# BAT32G157 register map
Vendor: Cmsemicon; Series: BAT32G157; File version: 1.0
CPU: CM0+ r0p1, little endian, no MPU, no FPU, VTOR, 2 interrupt priority bits
Registers are 8-bit, read-write, reset 0x0 unless marked. A register's access mark holds for its fields unless they carry their own. Offsets are from the block's base; [hi:lo] are bit positions; {n}, {i} and the like mark numbered series; 'fields as' and 'values as' point back to an identical list.

## USBF — USB Full Speed Module
Base 0x40080000
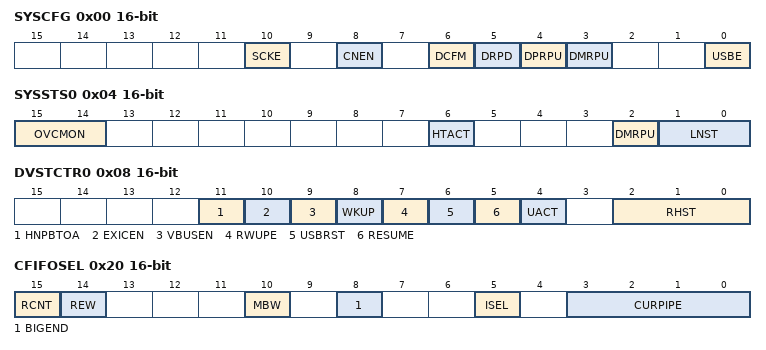
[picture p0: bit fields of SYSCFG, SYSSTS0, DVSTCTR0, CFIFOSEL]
0x00 SYSCFG 16-bit — System Configuration Control Register
  [10] SCKE — USB Clock Enable
  [8] CNEN — CNEN Single-Ended Receiver Enable
  [6] DCFM — Controller Function Select
  [5] DRPD — D+/D- Line Resistor Control
  [4] DPRPU — D+ Line Resistor Control
  [3] DMRPU — D- Line Resistor Control
  [0] USBE — USBFS Operation Enable
0x04 SYSSTS0 16-bit — System Configuration Status Register 0
  [15:14] OVCMON — External USB_OVRCURA/USB_OVRCURB Input Pin Monitor
  [6] HTACT — USB Host Sequencer Status Monitor
  [2] DMRPU — External ID0 Input Pin Monitor
  [1:0] LNST — USB Data Line Status Monitor
0x08 DVSTCTR0 16-bit — Device State Control Register 0
  [11] HNPBTOA — Host Negotiation Protocol (HNP) Control
  [10] EXICEN — USB_EXICEN Output Pin Contro
  [9] VBUSEN — USB_VBUSEN Output Pin Control
  [8] WKUP — Wakeup Output
  [7] RWUPE — Wakeup Detection Enable
  [6] USBRST — USB Bus Reset Output
  [5] RESUME — Resume Output
  [4] UACT — USB Bus Enable
  [2:0] RHST — USB Bus Reset Status
0x14 CFIFO 16-bit — CFIFO Port Register
0x14 CFIFOL (alternate view of CFIFO) — CFIFO Port Register
0x18 D0FIFO 16-bit — D0FIFO Port Register
0x18 D0FIFOL (alternate view of D0FIFO) — D0FIFO Port Register
0x1C D1FIFO 16-bit — D1FIFO Port Register
0x1C D1FIFOL (alternate view of D1FIFO) — D1FIFO Port Register
0x20 CFIFOSEL 16-bit — CFIFO Port Select Register
  [15] RCNT — Read Count Mode
  [14] REW — USB_EXICEN Output Pin Contro
  [10] MBW — CFIFO Port Access Bit Width
  [8] BIGEND — CFIFO Port Endian Control
  [5] ISEL — CFIFO Port Access Direction When DCP is Selected
  [3:0] CURPIPE — CFIFO Port Access Pipe Specification
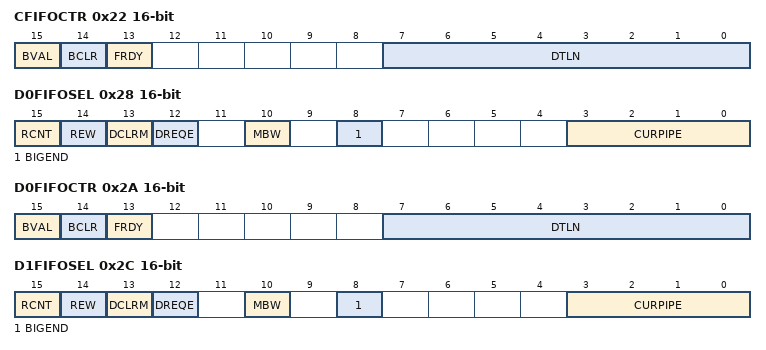
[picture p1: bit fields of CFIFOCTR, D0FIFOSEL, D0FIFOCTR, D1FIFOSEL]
0x22 CFIFOCTR 16-bit — CFIFO Port Control Register
  [15] BVAL — Buffer Memory Valid Flag
  [14] BCLR — CPU Buffer Clear
  [13] FRDY — FIFO Port Ready
  [7:0] DTLN — Receive Data Length
0x28 D0FIFOSEL 16-bit — D0FIFO Port Select Register
  [15] RCNT — Read Count Mode
  [14] REW — USB_EXICEN Output Pin Contro
  [13] DCLRM — Auto Buffer Memory Clear Mode Accessed after Specified Pipe Data is Read
  [12] DREQE — DMA/DTC Transfer Request Enable
  [10] MBW — FIFO Port Access Bit Width
  [8] BIGEND — FIFO Port Endian Control
  [3:0] CURPIPE — FIFO Port Access Pipe Specification
0x2A D0FIFOCTR 16-bit — D1FIFO Port Control Register
  fields as CFIFOCTR
0x2C D1FIFOSEL 16-bit — D1FIFO Port Select Register
  fields as D0FIFOSEL
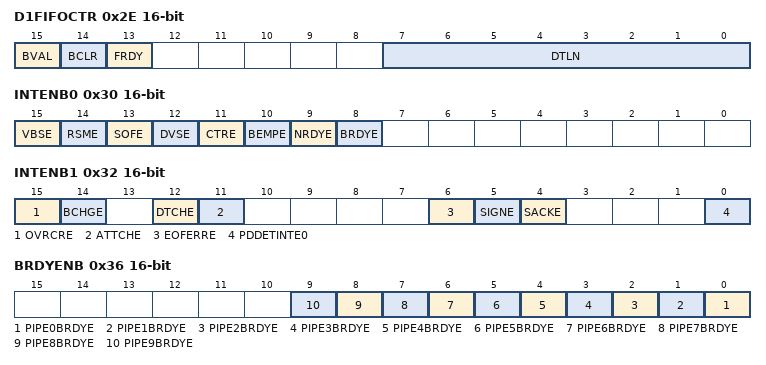
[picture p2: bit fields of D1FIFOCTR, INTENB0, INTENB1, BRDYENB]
0x2E D1FIFOCTR 16-bit — D1FIFO Port Control Register
  fields as CFIFOCTR
0x30 INTENB0 16-bit — Interrupt Enable Register 0
  [15] VBSE — VBUS Interrupt Enable
  [14] RSME — Resume Interrupt Enable
  [13] SOFE — Frame Number Update Interrupt Enable
  [12] DVSE — Device State Transition Interrupt Enable
  [11] CTRE — Control Transfer Stage Transition Interrupt Enable
  [10] BEMPE — Buffer Empty Interrupt Enable
  [9] NRDYE — Buffer Not Ready Response Interrupt Enable
  [8] BRDYE — Buffer Ready Interrupt Enable
0x32 INTENB1 16-bit — Interrupt Enable Register 1
  [15] OVRCRE — Overcurrent Input Change Interrupt Enable
  [14] BCHGE — USB Bus Change Interrupt Enable
  [12] DTCHE — Disconnection Detection Interrupt Enable
  [11] ATTCHE — Connection Detection Interrupt Enable
  [6] EOFERRE — Setup Transaction Error Interrupt Enable
  [5] SIGNE — Setup Transaction Error Interrupt Enable
  [4] SACKE — Setup Transaction Normal Response Interrupt Enable
  [0] PDDETINTE0 — PDDETINT0 Detection Interrupt Enable
0x36 BRDYENB 16-bit — BRDY Interrupt Enable Register
  [n] PIPE{n}BRDYE (n=0..9) — BRDY Interrupt Enable for Pipe {n}
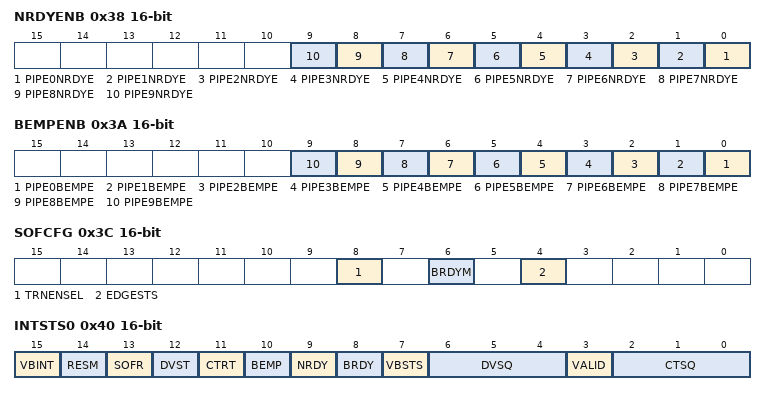
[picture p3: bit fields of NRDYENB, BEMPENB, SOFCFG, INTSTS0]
0x38 NRDYENB 16-bit — NRDY Interrupt Enable Register
  [n] PIPE{n}NRDYE (n=0..9) — NRDY Interrupt Enable for Pipe {n}
0x3A BEMPENB 16-bit — BEMP Interrupt Enable Register
  [n] PIPE{n}BEMPE (n=0..9) — BEMP Interrupt Enable for Pipe {n}
0x3C SOFCFG 16-bit — SOF Output Configuration Register
  [8] TRNENSEL — Transaction-Enabled Time Select
  [6] BRDYM — BRDY Interrupt Status Clear Timing
  [4] EDGESTS — Edge Interrupt Output Status Monitor
0x40 INTSTS0 16-bit — Interrupt Status Register 0
  [15] VBINT — VBUS Interrupt Status
  [14] RESM — Resume Interrupt Status
  [13] SOFR — Frame Number Update Interrupt Status
  [12] DVST — Device State Transition Interrupt Status
  [11] CTRT — Control Transfer Stage Transition Interrupt Status
  [10] BEMP — Buffer Empty Interrupt Status
  [9] NRDY — Buffer Not Ready Interrupt Status
  [8] BRDY — Buffer Ready Interrupt Status
  [7] VBSTS — VBUS Input Status
  [6:4] DVSQ — Device State
  [3] VALID — USB Request Reception
  [2:0] CTSQ — Control Transfer Stage
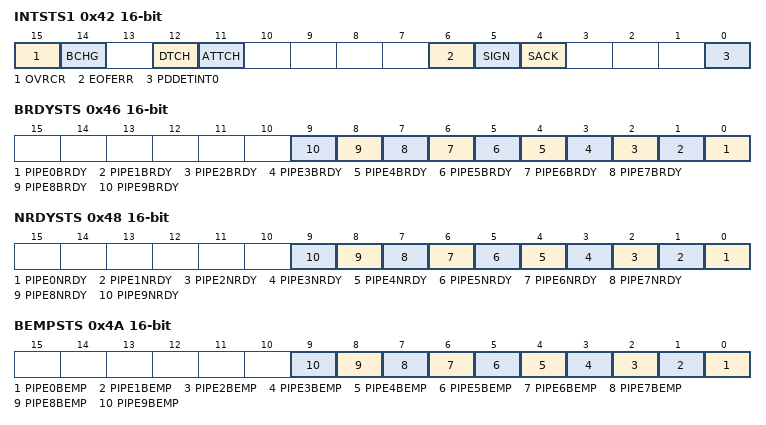
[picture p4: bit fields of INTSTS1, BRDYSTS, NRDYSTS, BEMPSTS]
0x42 INTSTS1 16-bit — Interrupt Status Register 1
  [15] OVRCR — Overcurrent Input Change Interrupt Status
  [14] BCHG — USB Bus Change Interrupt Status
  [12] DTCH — Disconnection Detection Interrupt Status
  [11] ATTCH — Connection Detection Interrupt Status
  [6] EOFERR — Setup Transaction Error Interrupt Status
  [5] SIGN — Setup Transaction Error Interrupt Status
  [4] SACK — Setup Transaction Normal Response Interrupt Status
  [0] PDDETINT0 — PDDETINT0 Detection Interrupt Status
0x46 BRDYSTS 16-bit — BRDY Interrupt Status Register
  [n] PIPE{n}BRDY (n=0..9) — BRDY Interrupt Status for Pipe {n}
0x48 NRDYSTS 16-bit — NRDY Interrupt Status Register
  [n] PIPE{n}NRDY (n=0..9) — NRDY Interrupt Status for Pipe {n}
0x4A BEMPSTS 16-bit — BEMP Interrupt Status Register
  [n] PIPE{n}BEMP (n=0..9) — BEMP Interrupt Status for Pipe {n}
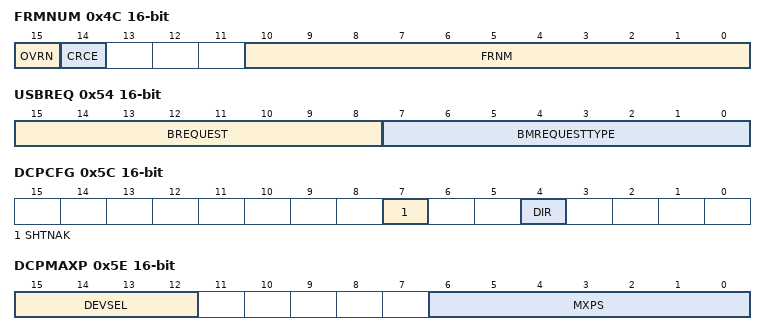
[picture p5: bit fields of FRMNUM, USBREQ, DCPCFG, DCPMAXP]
0x4C FRMNUM 16-bit — Frame Number Register
  [15] OVRN — Overrun/Underrun Detection Status
  [14] CRCE — Receive Data Error
  [10:0] FRNM ro — Frame Number
0x54 USBREQ 16-bit — USB Request Type Register
  [15:8] BREQUEST — Request
  [7:0] BMREQUESTTYPE — Request Type
0x56 USBVAL 16-bit — USB Request Value Register
0x58 USBINDX 16-bit — USB Request Index Register
0x5A USBLENG 16-bit — USB Request Length Register
0x5C DCPCFG 16-bit — DCP Configuration Register
  [7] SHTNAK — Pipe Disabled at End of Transfer
  [4] DIR — Transfer Direction
0x5E DCPMAXP 16-bit — DCP Maximum Packet Size Register
  [15:12] DEVSEL — Device Select
  [6:0] MXPS — Maximum Packet Size
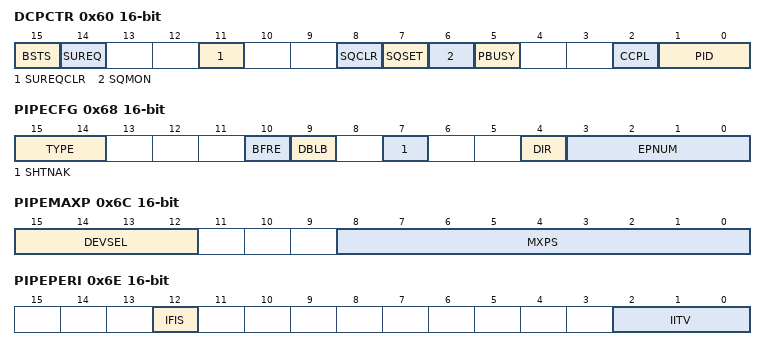
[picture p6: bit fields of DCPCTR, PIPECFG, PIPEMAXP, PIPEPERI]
0x60 DCPCTR 16-bit (reset mask 0xC9E3) — DCP Control Register
  [15] BSTS — Buffer Status
  [14] SUREQ — Setup Token Transmission
  [11] SUREQCLR — SUREQ Bit Clear
  [8] SQCLR — Sequence Toggle Bit Clear
  [7] SQSET — Sequence Toggle Bit Set
  [6] SQMON — Sequence Toggle Bit Monitor
  [5] PBUSY — Pipe Busy
  [2] CCPL — Control Transfer End Enable
  [1:0] PID — Response PID
0x64 PIPESEL 16-bit — Pipe Window Select Register
  [3:0] PIPESEL — Pipe Window Select
0x68 PIPECFG 16-bit — Pipe Configuration Register
  [15:14] TYPE — Transfer Type
  [10] BFRE — BRDY Interrupt Operation Specification
  [9] DBLB — Double Buffer Mode
  [7] SHTNAK — Pipe Disabled at End of Transfer
  [4] DIR — Transfer Direction
  [3:0] EPNUM — Endpoint Number
0x6C PIPEMAXP 16-bit — Pipe Maximum Packet Size Register
  [15:12] DEVSEL — Device Select
  [8:0] MXPS — Maximum Packet Size
0x6E PIPEPERI 16-bit — Pipe Cycle Control Register
  [12] IFIS — Isochronous IN Buffer Flush
  [2:0] IITV — Interval Error Detection Interval
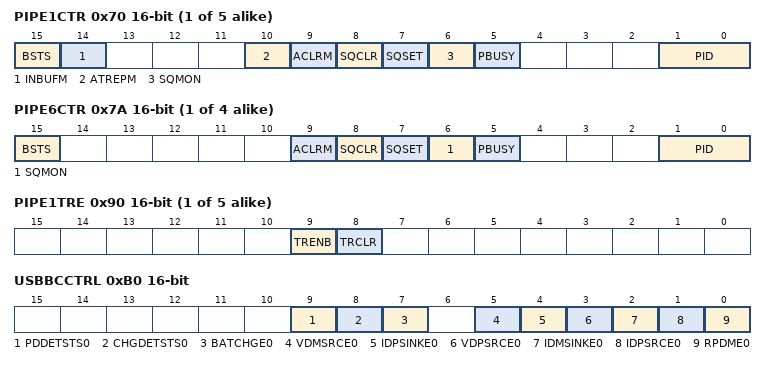
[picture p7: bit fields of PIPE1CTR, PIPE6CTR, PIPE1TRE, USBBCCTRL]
{0x6E+2i} PIPE{i}CTR 16-bit (i=1..5) — PIPE{i} Control Registers
  [15] BSTS — Buffer Status
  [14] INBUFM — Transmit Buffer Monitor
  [10] ATREPM — Auto Response Mode
  [9] ACLRM — Auto Buffer Clear Mode
  [8] SQCLR — Sequence Toggle Bit Clear
  [7] SQSET — Sequence Toggle Bit Set
  [6] SQMON — Sequence Toggle Bit Confirmation
  [5] PBUSY — Pipe Busy
  [1:0] PID — Response PID
{0x6E+2i} PIPE{i}CTR 16-bit (i=6..9) — PIPE{i} Control Registers
  [15] BSTS — Buffer Status
  [9] ACLRM — Auto Buffer Clear Mode
  [8] SQCLR — Sequence Toggle Bit Clear
  [7] SQSET — Sequence Toggle Bit Set
  [6] SQMON — Sequence Toggle Bit Confirmation
  [5] PBUSY — Pipe Busy
  [1:0] PID — Response PID
{0x8C+4i} PIPE{i}TRE (i=1..5) 16-bit — PIPE{i} Transaction Counter Enable Register
  [9] TRENB — Transaction Counter Enable
  [8] TRCLR — Transaction Counter Clear
{0x8E+4i} PIPE{i}TRN (i=1..5) 16-bit — PIPE{i} Transaction Counter Register
0xB0 USBBCCTRL 16-bit — BC Control Register 0
  [9] PDDETSTS0 — D+ Pin 0.6 V Input Detection Status
  [8] CHGDETSTS0 — D- Pin 0.6 V Input Detection Status
  [7] BATCHGE0 — BC (Battery Charger) Function General Enable Control
  [5] VDMSRCE0 — D- Pin VDMSRC (0.6 V) Output Contro
  [4] IDPSINKE0 — D+ Pin 0.6 V Input Detection (Comparator and Sink) Control
  [3] VDPSRCE0 — D+ Pin VDPSRC (0.6 V) Output Contro
  [2] IDMSINKE0 — D- Pin 0.6 V Input Detection (Comparator and Sink) Control
  [1] IDPSRCE0 — D+ Pin IDPSRC Output Control
  [0] RPDME0 — D- Pin Pull-Down Control
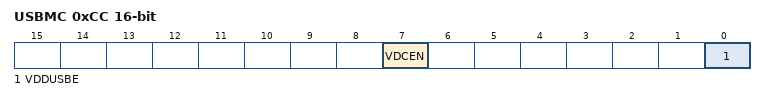
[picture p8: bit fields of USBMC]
0xCC USBMC 16-bit — USB Module Control Register
  [7] VDCEN — USB Regulator On/Off Control
  [0] VDDUSBE — USB Reference Power Supply Circuit On/Off Control
{0xD0+2i} DEVADDn{i} (i=0..5) 16-bit — Device Address {i} Configuration Register
  [7:6] USBSPD — Transfer Speed of Communication Target Device
